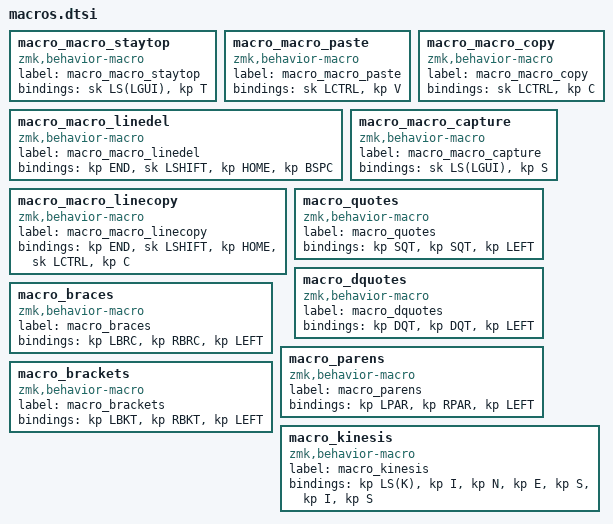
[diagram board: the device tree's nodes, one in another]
macro_macro_staytop: macro_macro_staytop{
compatible = "zmk,behavior-macro";
label = "macro_macro_staytop";
#binding-cells = <0>;
bindings = <&sk LS(LGUI)>, <&kp T>;
};
macro_macro_paste: macro_macro_paste{
compatible = "zmk,behavior-macro";
label = "macro_macro_paste";
#binding-cells = <0>;
bindings = <&sk LCTRL>, <&kp V>;
};
macro_macro_copy: macro_macro_copy{
compatible = "zmk,behavior-macro";
label = "macro_macro_copy";
#binding-cells = <0>;
bindings = <&sk LCTRL>, <&kp C>;
};
macro_macro_linedel: macro_macro_linedel{
compatible = "zmk,behavior-macro";
label = "macro_macro_linedel";
#binding-cells = <0>;
bindings = <&kp END>, <&sk LSHIFT>, <&kp HOME>, <&kp BSPC>;
};
macro_macro_capture: macro_macro_capture{
compatible = "zmk,behavior-macro";
label = "macro_macro_capture";
#binding-cells = <0>;
bindings = <&sk LS(LGUI)>, <&kp S>;
};
macro_macro_linecopy: macro_macro_linecopy{
compatible = "zmk,behavior-macro";
label = "macro_macro_linecopy";
#binding-cells = <0>;
bindings = <&kp END>, <&sk LSHIFT>, <&kp HOME>, <&sk LCTRL>, <&kp C>;
};
macro_quotes: macro_quotes{
compatible = "zmk,behavior-macro";
label = "macro_quotes";
#binding-cells = <0>;
bindings = <&kp SQT>, <&kp SQT>, <&kp LEFT>;
};
macro_dquotes: macro_dquotes{
compatible = "zmk,behavior-macro";
label = "macro_dquotes";
#binding-cells = <0>;
bindings = <&kp DQT>, <&kp DQT>, <&kp LEFT>;
};
macro_braces: macro_braces{
compatible = "zmk,behavior-macro";
label = "macro_braces";
#binding-cells = <0>;
bindings = <&kp LBRC>, <&kp RBRC>, <&kp LEFT>;
};
macro_parens: macro_parens{
compatible = "zmk,behavior-macro";
label = "macro_parens";
#binding-cells = <0>;
bindings = <&kp LPAR>, <&kp RPAR>, <&kp LEFT>;
};
macro_brackets: macro_brackets{
compatible = "zmk,behavior-macro";
label = "macro_brackets";
#binding-cells = <0>;
bindings = <&kp LBKT>, <&kp RBKT>, <&kp LEFT>;
};
macro_kinesis: macro_kinesis{
compatible = "zmk,behavior-macro";
label = "macro_kinesis";
#binding-cells = <0>;
bindings = <&kp LS(K)>, <&kp I>, <&kp N>, <&kp E>, <&kp S>, <&kp I>, <&kp S>;
};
